AUTOSAR XML (schema 00050)
package /Components
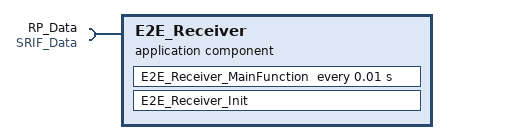
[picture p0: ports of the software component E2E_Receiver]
  application sw component type E2E_Receiver
    require port RP_Data: nonqueued-receiver-com-spec{data-element=Data, uses-end-to-end-protection=true, init-value=0}, required-interface=SRIF_Data
    behavior E2E_Receiver_IB: handle-termination-and-restart=NO-SUPPORT
      timing event TE_E2E_Receiver_MainFunction: start-on-event=E2E_Receiver_MainFunction, period=0.01
      runnable E2E_Receiver_Init
      runnable E2E_Receiver_MainFunction
        data-receive-point-by-arguments:
          access IN_RP_Data_Data: accessed-variable=RP_Data.Data
